# MSS_CTRL register map
Vendor: Texas Instruments
Peripheral module from a debugger description file (folder awr2x44p).
Registers are 32-bit, read-write, no defined reset value unless marked. A register's access mark holds for its fields unless they carry their own. Offsets are as the file gives them; lines under a group give offsets from that group; [hi:lo] are bit positions; {n}, {i} and the like mark numbered series; 'fields as' and 'values as' point back to an identical list; <NAME> marks a mode.

## MSS_CTRL (part 1 of 3)
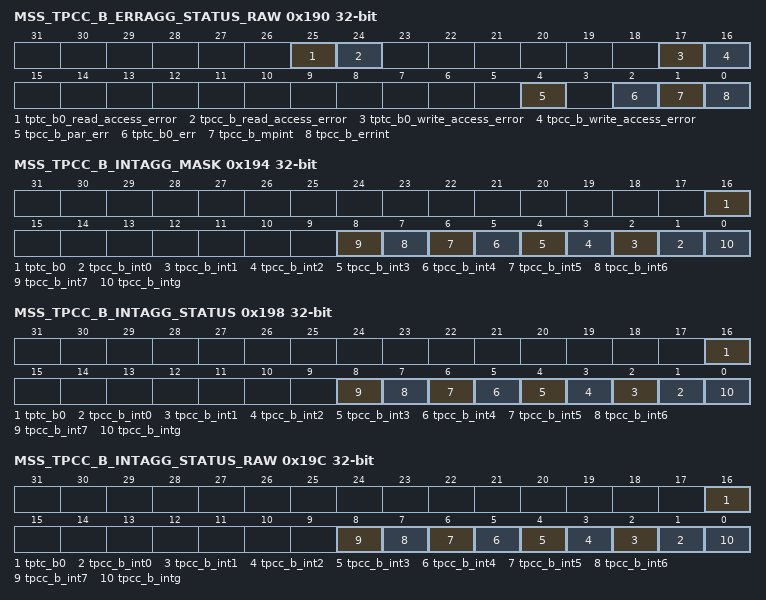
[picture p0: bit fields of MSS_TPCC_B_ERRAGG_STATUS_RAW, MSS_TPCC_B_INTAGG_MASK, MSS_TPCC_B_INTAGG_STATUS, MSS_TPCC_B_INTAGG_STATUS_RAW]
0x190 MSS_TPCC_B_ERRAGG_STATUS_RAW
  [25] tptc_b0_read_access_error — Rising Edge Capture reg (write 1 to clear): Raw Status of Error from MSS_TPTC_B0. Set irrespective if the Interupt is masked or unmasked in MSS_TPCC_B_ERRAGG_MASK
  [24] tpcc_b_read_access_error — Rising Edge Capture reg (write 1 to clear): Raw Status of Error from MSS_TPCC_B. Set irrespective if the Interupt is masked or unmasked in MSS_TPCC_B_ERRAGG_MASK
  [17] tptc_b0_write_access_error — Rising Edge Capture reg (write 1 to clear): Raw Status of Error from MSS_TPTC_B0. Set irrespective if the Interupt is masked or unmasked in MSS_TPCC_B_ERRAGG_MASK
  [16] tpcc_b_write_access_error — Rising Edge Capture reg (write 1 to clear): Raw Status of Error from MSS_TPCC_B. Set irrespective if the Interupt is masked or unmasked in MSS_TPCC_B_ERRAGG_MASK
  [4] tpcc_b_par_err — Rising Edge Capture reg (write 1 to clear): Raw Status of Error from MSS_TPCC_B. Set irrespective if the Interupt is masked or unmasked in MSS_TPCC_B_ERRAGG_MASK
  [2] tptc_b0_err — Rising Edge Capture reg (write 1 to clear): Raw Status of Error from MSS_TPTC_B0. Set irrespective if the Interupt is masked or unmasked in MSS_TPCC_B_ERRAGG_MASK
  [1] tpcc_b_mpint — Rising Edge Capture reg (write 1 to clear): Raw Status of Error from MSS_TPCC_B. Set irrespective if the Interupt is masked or unmasked in MSS_TPCC_B_ERRAGG_MASK
  [0] tpcc_b_errint — Rising Edge Capture reg (write 1 to clear): Raw Status of Error from MSS_TPCC_B. Set irrespective if the Interupt is masked or unmasked in MSS_TPCC_B_ERRAGG_MASK
0x194 MSS_TPCC_B_INTAGG_MASK
  [16] tptc_b0 — Mask Interrupt from TPTC A0 to aggregated Interrupt MSS_TPCC_A_INTAGG 1 : Interrupt is Masked 0 : Interrupt is Unmasked
  [n+1] tpcc_b_int{n} (n=0..7) — Mask Interrupt from MSS_TPCC_B to aggregated Interrupt MSS_TPCC_B_INTAGG 1 : Interrupt is Masked 0 : Interrupt is Unmasked
  [0] tpcc_b_intg — Mask Interrupt from MSS_TPCC_B to aggregated Interrupt MSS_TPCC_B_INTAGG 1 : Interrupt is Masked 0 : Interrupt is Unmasked
0x198 MSS_TPCC_B_INTAGG_STATUS
  [16] tptc_b0 — Rising Edge Capture reg (write 1 to clear): Status of Interrupt from TPTC A0. Set only if Interupt is unmasked in MSS_TPCC_A_INTAGG_MASK Wrie 0x1 to clear this interrupt.
  [n+1] tpcc_b_int{n} (n=0..7) — Rising Edge Capture reg (write 1 to clear): Status of Interrupt from MSS_TPCC_B. Set only if Interupt is unmasked in MSS_TPCC_B_INTAGG_MASK Wrie 0x1 to clear this interrupt.
  [0] tpcc_b_intg — Rising Edge Capture reg (write 1 to clear): Status of Interrupt from MSS_TPCC_B. Set only if Interupt is unmasked in MSS_TPCC_B_INTAGG_MASK Wrie 0x1 to clear this interrupt.
0x19C MSS_TPCC_B_INTAGG_STATUS_RAW
  [16] tptc_b0 — Rising Edge Capture reg (write 1 to clear): Raw Status of Interrupt from TPTC A0. Set irrespective if the Interupt is masked or unmasked in MSS_TPCC_A_INTAGG_MASK
  [n+1] tpcc_b_int{n} (n=0..7) — Rising Edge Capture reg (write 1 to clear): Raw Status of Interrupt from MSS_TPCC_B. Set irrespective if the Interupt is masked or unmasked in MSS_TPCC_C_INTAGG_MASK
  [0] tpcc_b_intg — Rising Edge Capture reg (write 1 to clear): Raw Status of Interrupt from MSS_TPCC_B. Set irrespective if the Interupt is masked or unmasked in MSS_TPCC_C_INTAGG_MASK
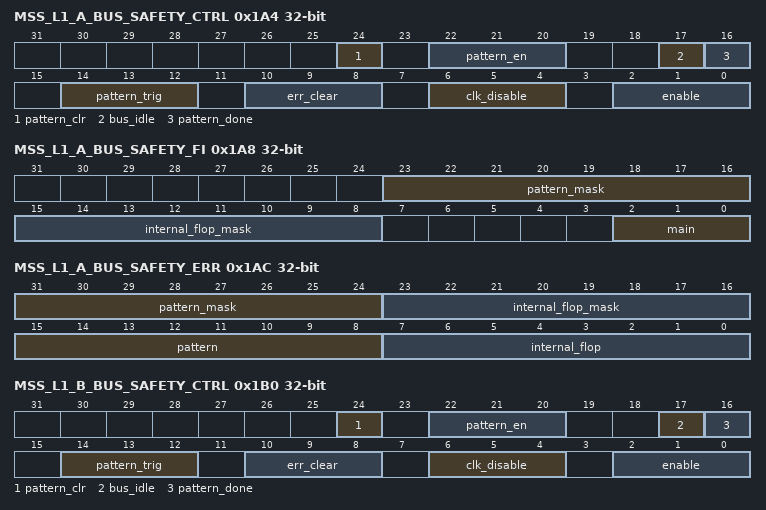
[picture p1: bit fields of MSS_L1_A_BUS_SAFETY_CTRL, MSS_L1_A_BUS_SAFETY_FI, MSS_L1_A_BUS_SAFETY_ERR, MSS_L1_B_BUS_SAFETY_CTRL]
0x1A4 MSS_L1_A_BUS_SAFETY_CTRL access per field
  [24] pattern_clr rw — Refer bus safety confluence page https://confluence.itg.ti.com/pages/viewpage.action?spaceKey=RadarPlatforms&title=Bus+Safety+-+AWR2944P
  [22:20] pattern_en rw — Refer bus safety confluence page https://confluence.itg.ti.com/pages/viewpage.action?spaceKey=RadarPlatforms&title=Bus+Safety+-+AWR2944P
  [17] bus_idle ro — Refer bus safety confluence page https://confluence.itg.ti.com/pages/viewpage.action?spaceKey=RadarPlatforms&title=Bus+Safety+-+AWR2944P
  [16] pattern_done ro — Refer bus safety confluence page https://confluence.itg.ti.com/pages/viewpage.action?spaceKey=RadarPlatforms&title=Bus+Safety+-+AWR2944P
  [14:12] pattern_trig rw — write pulse bit field:Refer bus safety confluence page https://confluence.itg.ti.com/pages/viewpage.action?spaceKey=RadarPlatforms&title=Bus+Safety+-+AWR2944P
  [10:8] err_clear rw — Refer bus safety confluence page https://confluence.itg.ti.com/pages/viewpage.action?spaceKey=RadarPlatforms&title=Bus+Safety+-+AWR2944P
  [6:4] clk_disable rw — Refer bus safety confluence page https://confluence.itg.ti.com/pages/viewpage.action?spaceKey=RadarPlatforms&title=Bus+Safety+-+AWR2944P
  [2:0] enable rw — Refer bus safety confluence page https://confluence.itg.ti.com/pages/viewpage.action?spaceKey=RadarPlatforms&title=Bus+Safety+-+AWR2944P
0x1A8 MSS_L1_A_BUS_SAFETY_FI
  [23:16] pattern_mask — Refer bus safety confluence page https://confluence.itg.ti.com/pages/viewpage.action?spaceKey=RadarPlatforms&title=Bus+Safety+-+AWR2944P
  [15:8] internal_flop_mask — Refer bus safety confluence page https://confluence.itg.ti.com/pages/viewpage.action?spaceKey=RadarPlatforms&title=Bus+Safety+-+AWR2944P
  [2:0] main — Refer bus safety confluence page https://confluence.itg.ti.com/pages/viewpage.action?spaceKey=RadarPlatforms&title=Bus+Safety+-+AWR2944P
0x1AC MSS_L1_A_BUS_SAFETY_ERR access per field
  [31:24] pattern_mask rw — Refer bus safety confluence page https://confluence.itg.ti.com/pages/viewpage.action?spaceKey=RadarPlatforms&title=Bus+Safety+-+AWR2944P
  [23:16] internal_flop_mask rw — Refer bus safety confluence page https://confluence.itg.ti.com/pages/viewpage.action?spaceKey=RadarPlatforms&title=Bus+Safety+-+AWR2944P
  [15:8] pattern ro — Refer bus safety confluence page https://confluence.itg.ti.com/pages/viewpage.action?spaceKey=RadarPlatforms&title=Bus+Safety+-+AWR2944P
  [7:0] internal_flop ro — Refer bus safety confluence page https://confluence.itg.ti.com/pages/viewpage.action?spaceKey=RadarPlatforms&title=Bus+Safety+-+AWR2944P
0x1B0 MSS_L1_B_BUS_SAFETY_CTRL access per field
  fields as MSS_L1_A_BUS_SAFETY_CTRL
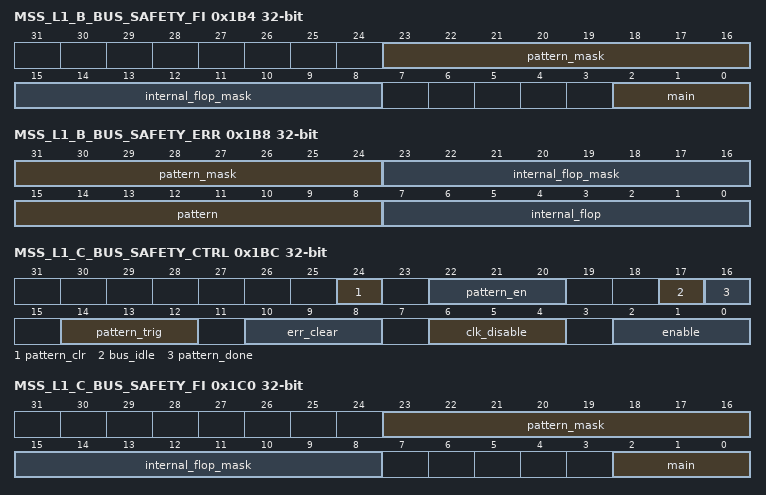
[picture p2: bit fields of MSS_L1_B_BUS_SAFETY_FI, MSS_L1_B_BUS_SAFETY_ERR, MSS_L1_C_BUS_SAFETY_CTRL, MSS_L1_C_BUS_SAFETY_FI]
0x1B4 MSS_L1_B_BUS_SAFETY_FI
  fields as MSS_L1_A_BUS_SAFETY_FI
0x1B8 MSS_L1_B_BUS_SAFETY_ERR access per field
  fields as MSS_L1_A_BUS_SAFETY_ERR
0x1BC MSS_L1_C_BUS_SAFETY_CTRL access per field
  fields as MSS_L1_A_BUS_SAFETY_CTRL
0x1C0 MSS_L1_C_BUS_SAFETY_FI
  fields as MSS_L1_A_BUS_SAFETY_FI
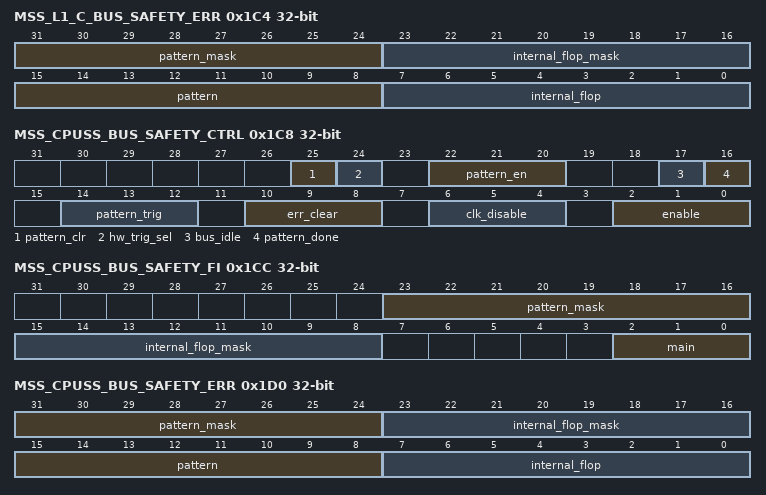
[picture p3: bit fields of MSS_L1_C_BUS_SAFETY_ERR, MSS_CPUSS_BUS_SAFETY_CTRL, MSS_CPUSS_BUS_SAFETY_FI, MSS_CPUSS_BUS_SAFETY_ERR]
0x1C4 MSS_L1_C_BUS_SAFETY_ERR access per field
  fields as MSS_L1_A_BUS_SAFETY_ERR
0x1C8 MSS_CPUSS_BUS_SAFETY_CTRL access per field
  [25] pattern_clr rw — Refer bus safety confluence page https://confluence.itg.ti.com/pages/viewpage.action?spaceKey=RadarPlatforms&title=Bus+Safety+-+AWR2944P
  [24] hw_trig_sel rw — Refer bus safety confluence page https://confluence.itg.ti.com/pages/viewpage.action?spaceKey=RadarPlatforms&title=Bus+Safety+-+AWR2944P
  [22:20] pattern_en rw — Refer bus safety confluence page https://confluence.itg.ti.com/pages/viewpage.action?spaceKey=RadarPlatforms&title=Bus+Safety+-+AWR2944P
  [17] bus_idle ro — Refer bus safety confluence page https://confluence.itg.ti.com/pages/viewpage.action?spaceKey=RadarPlatforms&title=Bus+Safety+-+AWR2944P
  [16] pattern_done ro — Refer bus safety confluence page https://confluence.itg.ti.com/pages/viewpage.action?spaceKey=RadarPlatforms&title=Bus+Safety+-+AWR2944P
  [14:12] pattern_trig rw — write pulse bit field:Refer bus safety confluence page https://confluence.itg.ti.com/pages/viewpage.action?spaceKey=RadarPlatforms&title=Bus+Safety+-+AWR2944P
  [10:8] err_clear rw — Refer bus safety confluence page https://confluence.itg.ti.com/pages/viewpage.action?spaceKey=RadarPlatforms&title=Bus+Safety+-+AWR2944P
  [6:4] clk_disable rw — Refer bus safety confluence page https://confluence.itg.ti.com/pages/viewpage.action?spaceKey=RadarPlatforms&title=Bus+Safety+-+AWR2944P
  [2:0] enable rw — Refer bus safety confluence page https://confluence.itg.ti.com/pages/viewpage.action?spaceKey=RadarPlatforms&title=Bus+Safety+-+AWR2944P
0x1CC MSS_CPUSS_BUS_SAFETY_FI
  fields as MSS_L1_A_BUS_SAFETY_FI
0x1D0 MSS_CPUSS_BUS_SAFETY_ERR access per field
  fields as MSS_L1_A_BUS_SAFETY_ERR
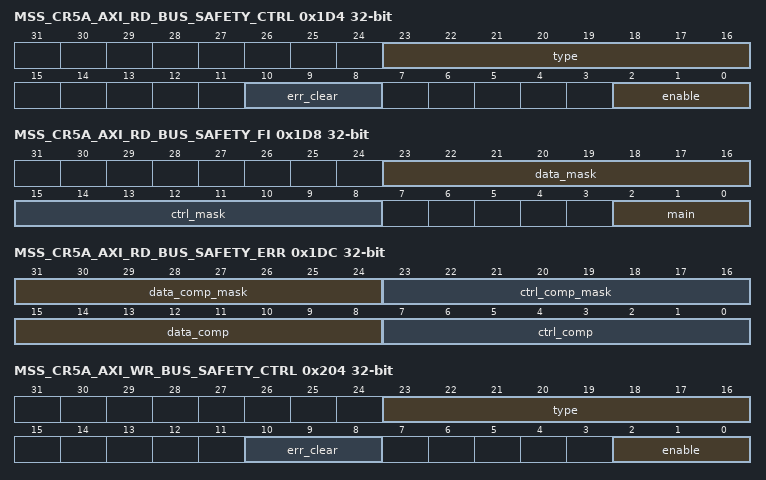
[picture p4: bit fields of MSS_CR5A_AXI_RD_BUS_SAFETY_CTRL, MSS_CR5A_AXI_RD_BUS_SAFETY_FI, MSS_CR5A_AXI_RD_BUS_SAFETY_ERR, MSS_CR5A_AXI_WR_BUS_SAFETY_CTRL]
0x1D4 MSS_CR5A_AXI_RD_BUS_SAFETY_CTRL access per field
  [23:16] type ro — undefined : command channel undefined : write channel undefined : write status channel undefined : read channel
  [10:8] err_clear rw — write pulse bit field:Refer bus safety confluence page https://confluence.itg.ti.com/pages/viewpage.action?spaceKey=RadarPlatforms&title=Bus+Safety+-+AWR2944P
  [2:0] enable rw — Refer bus safety confluence page https://confluence.itg.ti.com/pages/viewpage.action?spaceKey=RadarPlatforms&title=Bus+Safety+-+AWR2944P
0x1D8 MSS_CR5A_AXI_RD_BUS_SAFETY_FI
  [23:16] data_mask — Refer bus safety confluence page https://confluence.itg.ti.com/pages/viewpage.action?spaceKey=RadarPlatforms&title=Bus+Safety+-+AWR2944P
  [15:8] ctrl_mask — Refer bus safety confluence page https://confluence.itg.ti.com/pages/viewpage.action?spaceKey=RadarPlatforms&title=Bus+Safety+-+AWR2944P
  [2:0] main — Refer bus safety confluence page https://confluence.itg.ti.com/pages/viewpage.action?spaceKey=RadarPlatforms&title=Bus+Safety+-+AWR2944P
0x1DC MSS_CR5A_AXI_RD_BUS_SAFETY_ERR access per field
  [31:24] data_comp_mask rw — Refer bus safety confluence page https://confluence.itg.ti.com/pages/viewpage.action?spaceKey=RadarPlatforms&title=Bus+Safety+-+AWR2944P
  [23:16] ctrl_comp_mask rw — Refer bus safety confluence page https://confluence.itg.ti.com/pages/viewpage.action?spaceKey=RadarPlatforms&title=Bus+Safety+-+AWR2944P
  [15:8] data_comp ro — Refer bus safety confluence page https://confluence.itg.ti.com/pages/viewpage.action?spaceKey=RadarPlatforms&title=Bus+Safety+-+AWR2944P
  [7:0] ctrl_comp ro — Refer bus safety confluence page https://confluence.itg.ti.com/pages/viewpage.action?spaceKey=RadarPlatforms&title=Bus+Safety+-+AWR2944P
0x204 MSS_CR5A_AXI_WR_BUS_SAFETY_CTRL access per field
  fields as MSS_CR5A_AXI_RD_BUS_SAFETY_CTRL
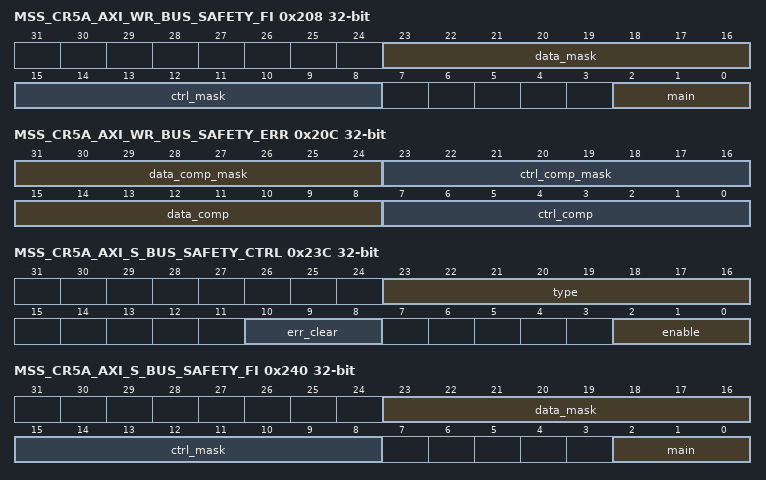
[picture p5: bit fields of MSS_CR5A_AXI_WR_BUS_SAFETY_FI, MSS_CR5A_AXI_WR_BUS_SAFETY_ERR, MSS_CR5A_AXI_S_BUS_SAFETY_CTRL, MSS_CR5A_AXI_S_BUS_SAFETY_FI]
0x208 MSS_CR5A_AXI_WR_BUS_SAFETY_FI
  fields as MSS_CR5A_AXI_RD_BUS_SAFETY_FI
0x20C MSS_CR5A_AXI_WR_BUS_SAFETY_ERR access per field
  fields as MSS_CR5A_AXI_RD_BUS_SAFETY_ERR
0x23C MSS_CR5A_AXI_S_BUS_SAFETY_CTRL access per field
  fields as MSS_CR5A_AXI_RD_BUS_SAFETY_CTRL
0x240 MSS_CR5A_AXI_S_BUS_SAFETY_FI
  fields as MSS_CR5A_AXI_RD_BUS_SAFETY_FI
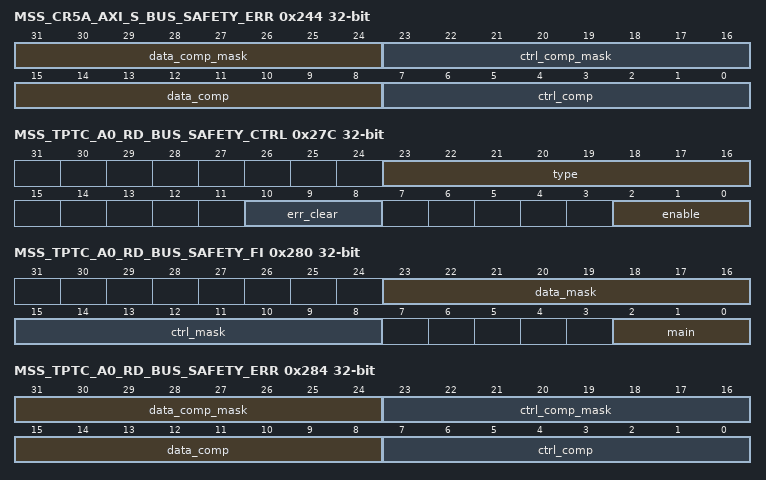
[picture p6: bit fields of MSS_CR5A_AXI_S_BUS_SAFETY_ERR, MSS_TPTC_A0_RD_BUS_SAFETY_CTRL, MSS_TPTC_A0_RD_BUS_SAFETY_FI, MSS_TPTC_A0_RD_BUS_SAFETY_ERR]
0x244 MSS_CR5A_AXI_S_BUS_SAFETY_ERR access per field
  fields as MSS_CR5A_AXI_RD_BUS_SAFETY_ERR
0x27C MSS_TPTC_A0_RD_BUS_SAFETY_CTRL access per field
  fields as MSS_CR5A_AXI_RD_BUS_SAFETY_CTRL
0x280 MSS_TPTC_A0_RD_BUS_SAFETY_FI
  fields as MSS_CR5A_AXI_RD_BUS_SAFETY_FI
0x284 MSS_TPTC_A0_RD_BUS_SAFETY_ERR access per field
  fields as MSS_CR5A_AXI_RD_BUS_SAFETY_ERR
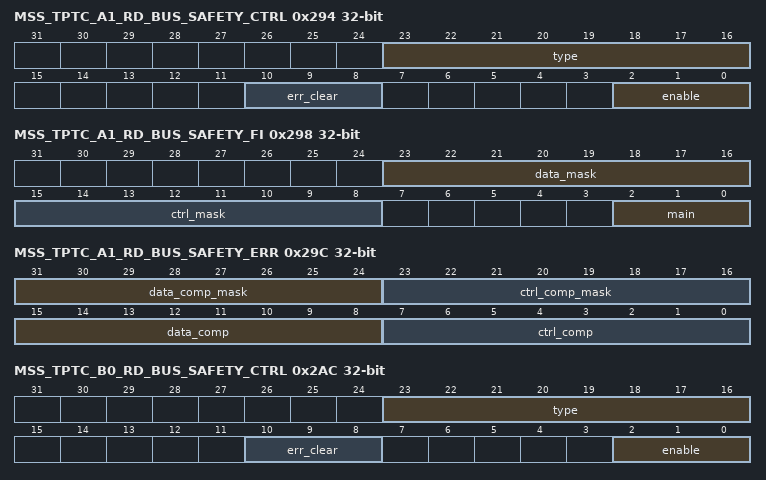
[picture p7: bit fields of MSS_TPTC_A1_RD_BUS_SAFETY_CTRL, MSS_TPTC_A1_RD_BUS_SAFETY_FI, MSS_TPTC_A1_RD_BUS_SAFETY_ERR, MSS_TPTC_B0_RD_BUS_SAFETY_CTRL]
0x294 MSS_TPTC_A1_RD_BUS_SAFETY_CTRL access per field
  fields as MSS_CR5A_AXI_RD_BUS_SAFETY_CTRL
0x298 MSS_TPTC_A1_RD_BUS_SAFETY_FI
  fields as MSS_CR5A_AXI_RD_BUS_SAFETY_FI
0x29C MSS_TPTC_A1_RD_BUS_SAFETY_ERR access per field
  fields as MSS_CR5A_AXI_RD_BUS_SAFETY_ERR
0x2AC MSS_TPTC_B0_RD_BUS_SAFETY_CTRL access per field
  fields as MSS_CR5A_AXI_RD_BUS_SAFETY_CTRL
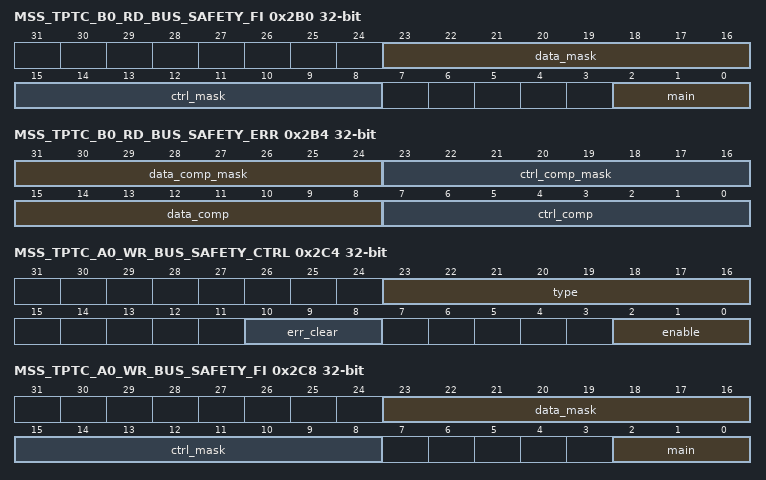
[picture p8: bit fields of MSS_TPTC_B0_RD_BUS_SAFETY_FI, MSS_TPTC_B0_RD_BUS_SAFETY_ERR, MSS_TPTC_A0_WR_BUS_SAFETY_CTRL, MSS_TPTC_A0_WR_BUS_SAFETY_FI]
0x2B0 MSS_TPTC_B0_RD_BUS_SAFETY_FI
  fields as MSS_CR5A_AXI_RD_BUS_SAFETY_FI
0x2B4 MSS_TPTC_B0_RD_BUS_SAFETY_ERR access per field
  fields as MSS_CR5A_AXI_RD_BUS_SAFETY_ERR
0x2C4 MSS_TPTC_A0_WR_BUS_SAFETY_CTRL access per field
  fields as MSS_CR5A_AXI_RD_BUS_SAFETY_CTRL
0x2C8 MSS_TPTC_A0_WR_BUS_SAFETY_FI
  fields as MSS_CR5A_AXI_RD_BUS_SAFETY_FI
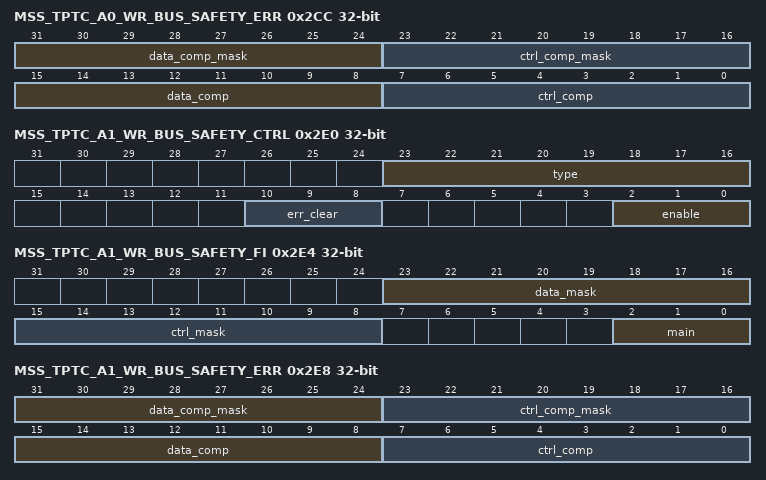
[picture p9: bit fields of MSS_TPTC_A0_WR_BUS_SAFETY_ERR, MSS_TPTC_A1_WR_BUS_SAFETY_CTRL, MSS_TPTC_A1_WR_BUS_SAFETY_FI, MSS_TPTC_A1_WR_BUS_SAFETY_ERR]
0x2CC MSS_TPTC_A0_WR_BUS_SAFETY_ERR access per field
  fields as MSS_CR5A_AXI_RD_BUS_SAFETY_ERR
0x2E0 MSS_TPTC_A1_WR_BUS_SAFETY_CTRL access per field
  fields as MSS_CR5A_AXI_RD_BUS_SAFETY_CTRL
0x2E4 MSS_TPTC_A1_WR_BUS_SAFETY_FI
  fields as MSS_CR5A_AXI_RD_BUS_SAFETY_FI
0x2E8 MSS_TPTC_A1_WR_BUS_SAFETY_ERR access per field
  fields as MSS_CR5A_AXI_RD_BUS_SAFETY_ERR
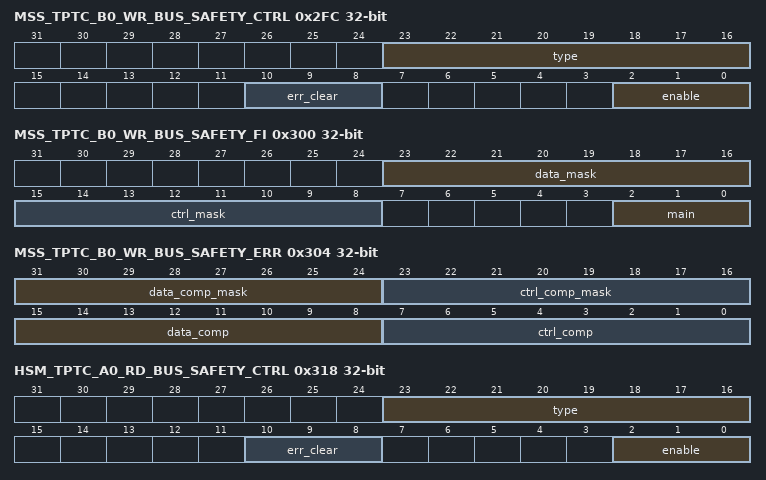
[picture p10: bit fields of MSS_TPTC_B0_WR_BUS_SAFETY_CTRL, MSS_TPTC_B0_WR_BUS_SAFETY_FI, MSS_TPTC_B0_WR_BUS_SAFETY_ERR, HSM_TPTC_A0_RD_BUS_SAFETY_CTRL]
0x2FC MSS_TPTC_B0_WR_BUS_SAFETY_CTRL access per field
  fields as MSS_CR5A_AXI_RD_BUS_SAFETY_CTRL
0x300 MSS_TPTC_B0_WR_BUS_SAFETY_FI
  fields as MSS_CR5A_AXI_RD_BUS_SAFETY_FI
0x304 MSS_TPTC_B0_WR_BUS_SAFETY_ERR access per field
  fields as MSS_CR5A_AXI_RD_BUS_SAFETY_ERR
0x318 HSM_TPTC_A0_RD_BUS_SAFETY_CTRL access per field
  fields as MSS_CR5A_AXI_RD_BUS_SAFETY_CTRL
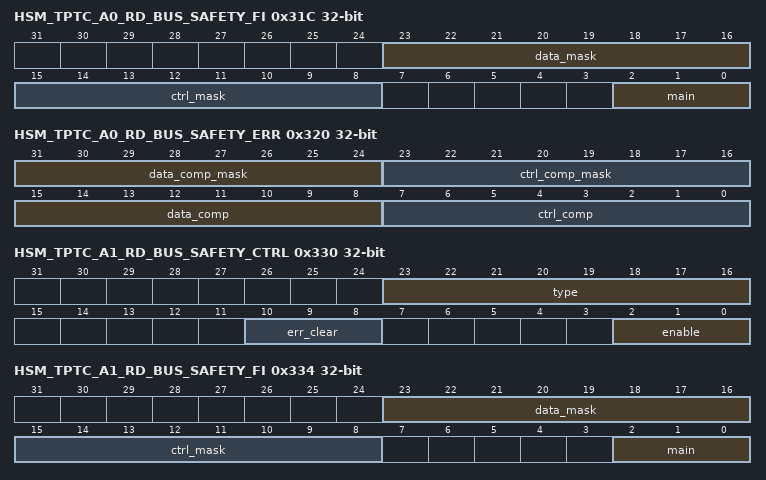
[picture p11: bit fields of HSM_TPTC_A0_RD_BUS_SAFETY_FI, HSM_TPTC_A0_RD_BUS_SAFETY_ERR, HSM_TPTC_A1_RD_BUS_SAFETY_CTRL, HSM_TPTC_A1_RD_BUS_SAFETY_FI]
0x31C HSM_TPTC_A0_RD_BUS_SAFETY_FI
  fields as MSS_CR5A_AXI_RD_BUS_SAFETY_FI
0x320 HSM_TPTC_A0_RD_BUS_SAFETY_ERR access per field
  fields as MSS_CR5A_AXI_RD_BUS_SAFETY_ERR
0x330 HSM_TPTC_A1_RD_BUS_SAFETY_CTRL access per field
  fields as MSS_CR5A_AXI_RD_BUS_SAFETY_CTRL
0x334 HSM_TPTC_A1_RD_BUS_SAFETY_FI
  fields as MSS_CR5A_AXI_RD_BUS_SAFETY_FI
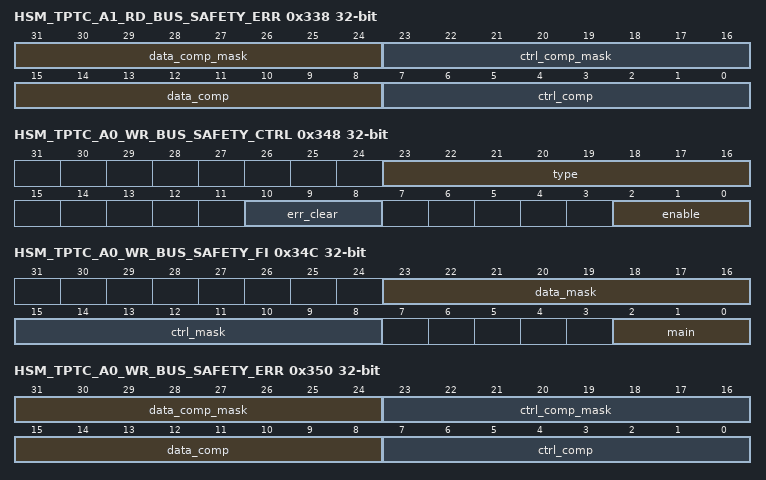
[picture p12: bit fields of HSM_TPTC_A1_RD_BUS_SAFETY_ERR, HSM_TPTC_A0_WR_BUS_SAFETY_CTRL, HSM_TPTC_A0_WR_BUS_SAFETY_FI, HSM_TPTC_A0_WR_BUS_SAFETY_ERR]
0x338 HSM_TPTC_A1_RD_BUS_SAFETY_ERR access per field
  fields as MSS_CR5A_AXI_RD_BUS_SAFETY_ERR
0x348 HSM_TPTC_A0_WR_BUS_SAFETY_CTRL access per field
  fields as MSS_CR5A_AXI_RD_BUS_SAFETY_CTRL
0x34C HSM_TPTC_A0_WR_BUS_SAFETY_FI
  fields as MSS_CR5A_AXI_RD_BUS_SAFETY_FI
0x350 HSM_TPTC_A0_WR_BUS_SAFETY_ERR access per field
  fields as MSS_CR5A_AXI_RD_BUS_SAFETY_ERR
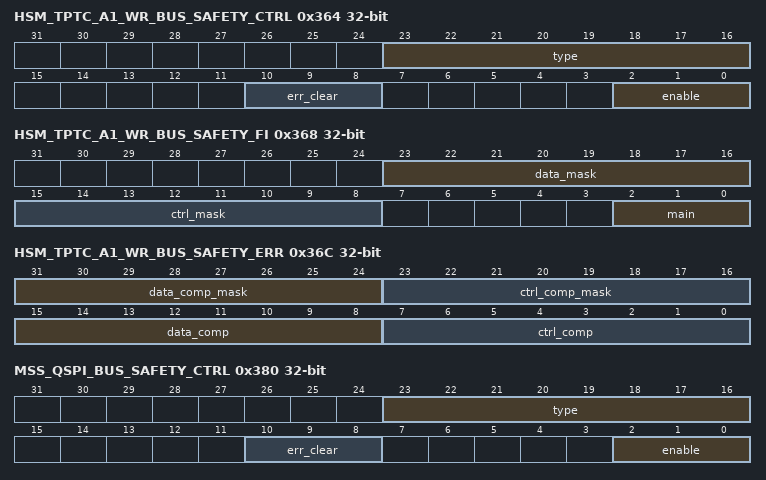
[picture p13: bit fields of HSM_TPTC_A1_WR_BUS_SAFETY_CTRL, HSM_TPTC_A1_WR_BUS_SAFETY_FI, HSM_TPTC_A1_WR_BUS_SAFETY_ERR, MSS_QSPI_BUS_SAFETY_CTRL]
0x364 HSM_TPTC_A1_WR_BUS_SAFETY_CTRL access per field
  fields as MSS_CR5A_AXI_RD_BUS_SAFETY_CTRL
0x368 HSM_TPTC_A1_WR_BUS_SAFETY_FI
  fields as MSS_CR5A_AXI_RD_BUS_SAFETY_FI
0x36C HSM_TPTC_A1_WR_BUS_SAFETY_ERR access per field
  fields as MSS_CR5A_AXI_RD_BUS_SAFETY_ERR
0x380 MSS_QSPI_BUS_SAFETY_CTRL access per field
  fields as MSS_CR5A_AXI_RD_BUS_SAFETY_CTRL
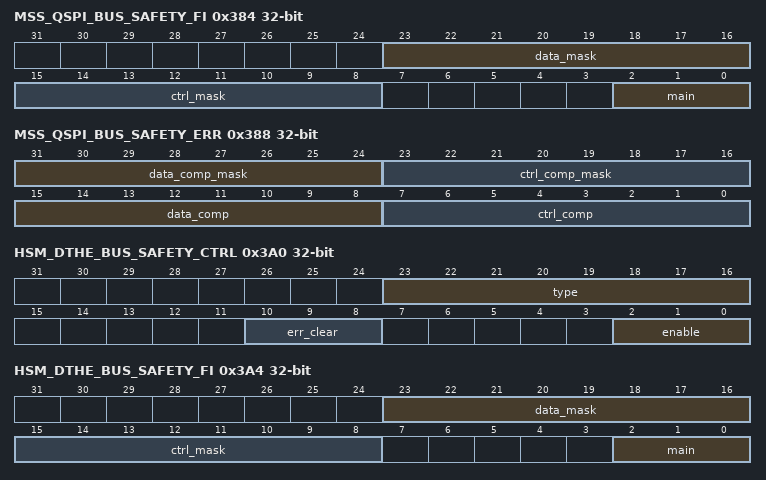
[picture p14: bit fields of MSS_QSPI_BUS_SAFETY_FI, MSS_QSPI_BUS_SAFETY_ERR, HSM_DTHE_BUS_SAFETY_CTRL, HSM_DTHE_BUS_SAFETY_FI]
0x384 MSS_QSPI_BUS_SAFETY_FI
  fields as MSS_CR5A_AXI_RD_BUS_SAFETY_FI
0x388 MSS_QSPI_BUS_SAFETY_ERR access per field
  fields as MSS_CR5A_AXI_RD_BUS_SAFETY_ERR
0x3A0 HSM_DTHE_BUS_SAFETY_CTRL access per field
  fields as MSS_CR5A_AXI_RD_BUS_SAFETY_CTRL
0x3A4 HSM_DTHE_BUS_SAFETY_FI
  fields as MSS_CR5A_AXI_RD_BUS_SAFETY_FI
0x3A8 HSM_DTHE_BUS_SAFETY_ERR access per field
  fields as MSS_CR5A_AXI_RD_BUS_SAFETY_ERR
0x3C0 MSS_CPSW_BUS_SAFETY_CTRL access per field
  fields as MSS_CR5A_AXI_RD_BUS_SAFETY_CTRL
0x3C4 MSS_CPSW_BUS_SAFETY_FI
  fields as MSS_CR5A_AXI_RD_BUS_SAFETY_FI
0x3C8 MSS_CPSW_BUS_SAFETY_ERR access per field
  fields as MSS_CR5A_AXI_RD_BUS_SAFETY_ERR
0x3E0 MSS_MCRC_BUS_SAFETY_CTRL access per field
  fields as MSS_CR5A_AXI_RD_BUS_SAFETY_CTRL
0x3E4 MSS_MCRC_BUS_SAFETY_FI
  fields as MSS_CR5A_AXI_RD_BUS_SAFETY_FI
0x3E8 MSS_MCRC_BUS_SAFETY_ERR access per field
  fields as MSS_CR5A_AXI_RD_BUS_SAFETY_ERR
0x400 MSS_PCR_BUS_SAFETY_CTRL access per field
  fields as MSS_CR5A_AXI_RD_BUS_SAFETY_CTRL
0x404 MSS_PCR_BUS_SAFETY_FI
  fields as MSS_CR5A_AXI_RD_BUS_SAFETY_FI
0x408 MSS_PCR_BUS_SAFETY_ERR access per field
  fields as MSS_CR5A_AXI_RD_BUS_SAFETY_ERR
0x420 MSS_PCR2_BUS_SAFETY_CTRL access per field
  fields as MSS_CR5A_AXI_RD_BUS_SAFETY_CTRL
0x424 MSS_PCR2_BUS_SAFETY_FI
  fields as MSS_CR5A_AXI_RD_BUS_SAFETY_FI
0x428 MSS_PCR2_BUS_SAFETY_ERR access per field
  fields as MSS_CR5A_AXI_RD_BUS_SAFETY_ERR
0x440 HSM_M_BUS_SAFETY_CTRL access per field
  fields as MSS_CR5A_AXI_RD_BUS_SAFETY_CTRL
0x444 HSM_M_BUS_SAFETY_FI
  fields as MSS_CR5A_AXI_RD_BUS_SAFETY_FI
0x448 HSM_M_BUS_SAFETY_ERR access per field
  fields as MSS_CR5A_AXI_RD_BUS_SAFETY_ERR
0x460 HSM_S_BUS_SAFETY_CTRL access per field
  fields as MSS_CR5A_AXI_RD_BUS_SAFETY_CTRL
0x464 HSM_S_BUS_SAFETY_FI
  fields as MSS_CR5A_AXI_RD_BUS_SAFETY_FI
0x468 HSM_S_BUS_SAFETY_ERR access per field
  fields as MSS_CR5A_AXI_RD_BUS_SAFETY_ERR
0x480 DAP_R232_BUS_SAFETY_CTRL access per field
  fields as MSS_CR5A_AXI_RD_BUS_SAFETY_CTRL
0x484 DAP_R232_BUS_SAFETY_FI
  fields as MSS_CR5A_AXI_RD_BUS_SAFETY_FI
0x488 DAP_R232_BUS_SAFETY_ERR access per field
  fields as MSS_CR5A_AXI_RD_BUS_SAFETY_ERR
0x4A0 MSS_L2_A_BUS_SAFETY_CTRL access per field
  fields as MSS_CR5A_AXI_RD_BUS_SAFETY_CTRL
0x4A4 MSS_L2_A_BUS_SAFETY_FI
  fields as MSS_CR5A_AXI_RD_BUS_SAFETY_FI
0x4A8 MSS_L2_A_BUS_SAFETY_ERR access per field
  fields as MSS_CR5A_AXI_RD_BUS_SAFETY_ERR
0x4C0 MSS_L2_B_BUS_SAFETY_CTRL access per field
  fields as MSS_CR5A_AXI_RD_BUS_SAFETY_CTRL
0x4C4 MSS_L2_B_BUS_SAFETY_FI
  fields as MSS_CR5A_AXI_RD_BUS_SAFETY_FI
0x4C8 MSS_L2_B_BUS_SAFETY_ERR access per field
  fields as MSS_CR5A_AXI_RD_BUS_SAFETY_ERR
0x4E0 MSS_MBOX_BUS_SAFETY_CTRL access per field
  fields as MSS_CR5A_AXI_RD_BUS_SAFETY_CTRL
0x4E4 MSS_MBOX_BUS_SAFETY_FI
  fields as MSS_CR5A_AXI_RD_BUS_SAFETY_FI
0x4E8 MSS_MBOX_BUS_SAFETY_ERR access per field
  fields as MSS_CR5A_AXI_RD_BUS_SAFETY_ERR
0x500 MSS_SWBUF_BUS_SAFETY_CTRL access per field
  fields as MSS_CR5A_AXI_RD_BUS_SAFETY_CTRL
0x504 MSS_SWBUF_BUS_SAFETY_FI
  fields as MSS_CR5A_AXI_RD_BUS_SAFETY_FI
0x508 MSS_SWBUF_BUS_SAFETY_ERR access per field
  fields as MSS_CR5A_AXI_RD_BUS_SAFETY_ERR
0x520 MSS_GPADC_BUS_SAFETY_CTRL access per field
  fields as MSS_CR5A_AXI_RD_BUS_SAFETY_CTRL
0x524 MSS_GPADC_BUS_SAFETY_FI
  fields as MSS_CR5A_AXI_RD_BUS_SAFETY_FI
0x528 MSS_GPADC_BUS_SAFETY_ERR access per field
  fields as MSS_CR5A_AXI_RD_BUS_SAFETY_ERR
0x548 HW_REG0
  [31:0] hwreg0 — HW reserved Regsiter
0x54C HW_REG1
  [31:0] hwreg1 — HW reserved Regsiter
0x550 PREVIOUS_NAME
  [31:1] hwreg2 — HW reserved Register
  [0] CPSW_CLK_STOP_REQ — CPSW clock stop req
0x554 HW_REG3 ro
  [31:9] hwreg3 — HW reserved Register
  [8] CPSW_CLK_STOP_IDLE — CPSW clock stop idle
  [4] CPSW_CLK_STOP_ACK — CPSW clock stop ack
  [0] ro — This denotes the status of ping_pong_sel bit.
0x558 HW_REG4
  [31:0] mss_pcrA_timeout_cfg — Configures the timeout value for MSS_PCRA.
{0x548+4i} HW_REG{i} (i=5..7)
  [31:0] hwreg{i} — HW reserved Register
0x568 MSS_DMM_BUS_SAFETY_CTRL access per field
  fields as MSS_CR5A_AXI_RD_BUS_SAFETY_CTRL
0x56C MSS_DMM_BUS_SAFETY_FI
  fields as MSS_CR5A_AXI_RD_BUS_SAFETY_FI
0x570 MSS_DMM_BUS_SAFETY_ERR access per field
  fields as MSS_CR5A_AXI_RD_BUS_SAFETY_ERR
0x588 MSS_DMM_SLV_BUS_SAFETY_CTRL access per field
  fields as MSS_CR5A_AXI_RD_BUS_SAFETY_CTRL
0x58C MSS_DMM_SLV_BUS_SAFETY_FI
  fields as MSS_CR5A_AXI_RD_BUS_SAFETY_FI
0x590 MSS_DMM_SLV_BUS_SAFETY_ERR access per field
  fields as MSS_CR5A_AXI_RD_BUS_SAFETY_ERR
0x5A8 MSS_TO_MDO_BUS_SAFETY_CTRL access per field
  fields as MSS_CR5A_AXI_RD_BUS_SAFETY_CTRL
0x5AC MSS_TO_MDO_BUS_SAFETY_FI
  fields as MSS_CR5A_AXI_RD_BUS_SAFETY_FI
0x5B0 MSS_TO_MDO_BUS_SAFETY_ERR access per field
  fields as MSS_CR5A_AXI_RD_BUS_SAFETY_ERR
0x5C8 MSS_SCRP_BUS_SAFETY_CTRL access per field
  [23:16] type ro — undefined : command channel undefined : write channel undefined : write status channel undefined : read channel
  [8] err_clear rw — write pulse bit field:Refer bus safety confluence page https://confluence.itg.ti.com/pages/viewpage.action?spaceKey=RadarPlatforms&title=Bus+Safety+-+AWR2944P
  [2:0] enable rw — Refer bus safety confluence page https://confluence.itg.ti.com/pages/viewpage.action?spaceKey=RadarPlatforms&title=Bus+Safety+-+AWR2944P
0x5CC MSS_SCRP_BUS_SAFETY_FI
  [31:24] safe — write pulse bit field:Refer bus safety confluence page https://confluence.itg.ti.com/pages/viewpage.action?spaceKey=RadarPlatforms&title=Bus+Safety+-+AWR2944P
  [23:16] main — write pulse bit field:Refer bus safety confluence page https://confluence.itg.ti.com/pages/viewpage.action?spaceKey=RadarPlatforms&title=Bus+Safety+-+AWR2944P
  [15:8] data — Refer bus safety confluence page https://confluence.itg.ti.com/pages/viewpage.action?spaceKey=RadarPlatforms&title=Bus+Safety+-+AWR2944P
  [5] ded — Refer bus safety confluence page https://confluence.itg.ti.com/pages/viewpage.action?spaceKey=RadarPlatforms&title=Bus+Safety+-+AWR2944P
  [4] sec — Refer bus safety confluence page https://confluence.itg.ti.com/pages/viewpage.action?spaceKey=RadarPlatforms&title=Bus+Safety+-+AWR2944P
  [3] global_safe_req — write pulse bit field:Refer bus safety confluence page https://confluence.itg.ti.com/pages/viewpage.action?spaceKey=RadarPlatforms&title=Bus+Safety+-+AWR2944P
  [2] global_main_req — write pulse bit field:Refer bus safety confluence page https://confluence.itg.ti.com/pages/viewpage.action?spaceKey=RadarPlatforms&title=Bus+Safety+-+AWR2944P
  [1] global_safe — write pulse bit field:Refer bus safety confluence page https://confluence.itg.ti.com/pages/viewpage.action?spaceKey=RadarPlatforms&title=Bus+Safety+-+AWR2944P
  [0] global_main — write pulse bit field:Refer bus safety confluence page https://confluence.itg.ti.com/pages/viewpage.action?spaceKey=RadarPlatforms&title=Bus+Safety+-+AWR2944P
0x5D0 MSS_SCRP_BUS_SAFETY_ERR ro
  [31:24] ded — Refer bus safety confluence page https://confluence.itg.ti.com/pages/viewpage.action?spaceKey=RadarPlatforms&title=Bus+Safety+-+AWR2944P
  [23:16] sec — Refer bus safety confluence page https://confluence.itg.ti.com/pages/viewpage.action?spaceKey=RadarPlatforms&title=Bus+Safety+-+AWR2944P
  [15:8] comp_check — Refer bus safety confluence page https://confluence.itg.ti.com/pages/viewpage.action?spaceKey=RadarPlatforms&title=Bus+Safety+-+AWR2944P
  [7:0] comp_err — Refer bus safety confluence page https://confluence.itg.ti.com/pages/viewpage.action?spaceKey=RadarPlatforms&title=Bus+Safety+-+AWR2944P
0x5D4 MSS_SCRP_BUS_SAFETY_ERR_STAT_DATA0 ro
  [15:8] d1 — Refer bus safety confluence page https://confluence.itg.ti.com/pages/viewpage.action?spaceKey=RadarPlatforms&title=Bus+Safety+-+AWR2944P
  [7:0] d0 — Refer bus safety confluence page https://confluence.itg.ti.com/pages/viewpage.action?spaceKey=RadarPlatforms&title=Bus+Safety+-+AWR2944P
0x5D8 MSS_SCRP_BUS_SAFETY_ERR_STAT_CMD ro
  [31:0] stat — Refer bus safety confluence page https://confluence.itg.ti.com/pages/viewpage.action?spaceKey=RadarPlatforms&title=Bus+Safety+-+AWR2944P
0x5DC MSS_SCRP_BUS_SAFETY_ERR_STAT_WRITE ro
  fields as MSS_SCRP_BUS_SAFETY_ERR_STAT_CMD
0x5E0 MSS_SCRP_BUS_SAFETY_ERR_STAT_READ ro
  fields as MSS_SCRP_BUS_SAFETY_ERR_STAT_CMD
0x5E4 MSS_SCRP_BUS_SAFETY_ERR_STAT_WRITERESP ro
  fields as MSS_SCRP_BUS_SAFETY_ERR_STAT_CMD
0x5E8 MSS_CR5A_AHB_BUS_SAFETY_CTRL access per field
  fields as MSS_SCRP_BUS_SAFETY_CTRL
0x5EC MSS_CR5A_AHB_BUS_SAFETY_FI
  fields as MSS_SCRP_BUS_SAFETY_FI
0x5F0 MSS_CR5A_AHB_BUS_SAFETY_ERR ro
  fields as MSS_SCRP_BUS_SAFETY_ERR
0x5F4 MSS_CR5A_AHB_BUS_SAFETY_ERR_STAT_DATA0 ro
  fields as MSS_SCRP_BUS_SAFETY_ERR_STAT_DATA0
0x5F8 MSS_CR5A_AHB_BUS_SAFETY_ERR_STAT_CMD ro
  fields as MSS_SCRP_BUS_SAFETY_ERR_STAT_CMD
0x5FC MSS_CR5A_AHB_BUS_SAFETY_ERR_STAT_WRITE ro
  fields as MSS_SCRP_BUS_SAFETY_ERR_STAT_CMD
0x600 MSS_CR5A_AHB_BUS_SAFETY_ERR_STAT_READ ro
  fields as MSS_SCRP_BUS_SAFETY_ERR_STAT_CMD
0x604 MSS_CR5A_AHB_BUS_SAFETY_ERR_STAT_WRITERESP ro
  fields as MSS_SCRP_BUS_SAFETY_ERR_STAT_CMD
0x628 DMM_CTRL_REG
  [0] dmm_pad_select — 0: SOC will be able to send the packet to DMMA/B 1: PAD will be able to send the packet to DMMA/B controlling from PAD
0x62C MSS_CR5A_MBOX_WRITE_DONE
  [4n] proc_{n} (n=0..7) — Write pulse bit field: This register should be written once finishing writing into the mailbox memory of processor {n}
0x630 MSS_CR5A_MBOX_READ_REQ
  [4n] proc_{n} (n=0..7) — Rising Edge Capture reg (write 1 to clear): This is request from processor {n} to mss_cr5a. Requesting it to read from mailbox.
0x634 MSS_CR5A_MBOX_READ_DONE
  [4n] proc_{n} (n=0..7) — Rising Edge Capture reg (write 1 to clear): This register should be written once finishing reading from CR5A's mailbox written by proc {n}
0x644 MSS_PBIST_KEY_RST
  [7:4] pbist_st_rst — MSS PBIST controller will be brought out of reset when value is 0xA
  [3:0] pbist_st_key — Top PBIST Selftest Key. Valid value is 0x5
{0x648+4i} MSS_PBIST_REG{i} (i=0..2)
  [31:0] pbist_reg — 0
0x654 MSS_QSPI_CONFIG
  [10:8] clk_loopback — Write 3'b111 to take board level loop back clock for QSPI
  [2:0] ext_clk — Write 3'b111 to external clock as QSPI baud clock source needed for DFT IO char.
0x658 MSS_STC_CONTROL
  [2:0] cr5_wfi_overide — writing 3'b111 will bypass the wfi signals from R5SS.
0x65C MSS_CTI_TRIG_SEL
  [7:0] trig8_sel — Used for selecting the trigger source for 8th trigger of MSS_CTI
0x660 MSS_DBGSS_CTI_TRIG_SEL
  [23:16] trig3 — Used for selecting the trigger source for 3rd trigger of ONE_MCU_CTI
  [15:8] trig2 — Used for selecting the trigger source for 2nd trigger of ONE_MCU_CTI
  [7:0] trig1 — Used for selecting the trigger source for 1st trigger of ONE_MCU_CTI
{0x664+4i} MSS_BOOT_INFO_REG{i} (i=0..7)
  [31:0] config — Reserved Register for Software use
0x684 MSS_TPTC_ECCAGGR_CLK_CNTRL
  [2] tptc_B0 — Writing '0' will gate the clock to TPTC_B0-FIFO during ECC-AGGR interaction(fault injection)
  [1] tptc_A1 — Writing '0' will gate the clock to TPTC_A1-FIFO during ECC-AGGR interaction(fault injection)
  [0] tptc_A0 — Writing '0' will gate the clock to TPTC_A0-FIFO during ECC-AGGR interaction(fault injection)
0x688 MSS_PERIPH_ERRAGG_MASK0
  [27] top_mdo_wr — Mask Interrupt from TOP_MDO to aggregated Interrupt MSS_PERIPH_ACCESS_ERRAGG 1 : Interrupt is Masked 0 : Interrupt is Unmasked
  [26] top_mdo_rd — Mask Interrupt from TOP_MDO to aggregated Interrupt MSS_PERIPH_ACCESS_ERRAGG 1 : Interrupt is Masked 0 : Interrupt is Unmasked
  [25] rcss_rcm_wr — Mask Interrupt from RSS_RCM to aggregated Interrupt MSS_PERIPH_ACCESS_ERRAGG 1 : Interrupt is Masked 0 : Interrupt is Unmasked
  [24] rcss_rcm_rd — Mask Interrupt from RSS_RCM to aggregated Interrupt MSS_PERIPH_ACCESS_ERRAGG 1 : Interrupt is Masked 0 : Interrupt is Unmasked
  [23] rcss_ctrl_wr — Mask Interrupt from RSS_CTRL to aggregated Interrupt MSS_PERIPH_ACCESS_ERRAGG 1 : Interrupt is Masked 0 : Interrupt is Unmasked
  [22] rcss_ctrl_rd — Mask Interrupt from RSS_CTRL to aggregated Interrupt MSS_PERIPH_ACCESS_ERRAGG 1 : Interrupt is Masked 0 : Interrupt is Unmasked
  [21] hwa_cfg_wr — Mask Interrupt from HWA_CFG to aggregated Interrupt MSS_PERIPH_ACCESS_ERRAGG 1 : Interrupt is Masked 0 : Interrupt is Unmasked
  [20] hwa_cfg_rd — Mask Interrupt from HWA_CFG to aggregated Interrupt MSS_PERIPH_ACCESS_ERRAGG 1 : Interrupt is Masked 0 : Interrupt is Unmasked
  [19] dss_cm4_ctrl_wr — Mask Interrupt from DSS_CM4_CTRL to aggregated Interrupt MSS_PERIPH_ACCESS_ERRAGG 1 : Interrupt is Masked 0 : Interrupt is Unmasked
  [18] dss_cm4_ctrl_rd — Mask Interrupt from DSS_CM4_CTRL to aggregated Interrupt MSS_PERIPH_ACCESS_ERRAGG 1 : Interrupt is Masked 0 : Interrupt is Unmasked
  [17] dss_rcm_wr — Mask Interrupt from DSS_RCM to aggregated Interrupt MSS_PERIPH_ACCESS_ERRAGG 1 : Interrupt is Masked 0 : Interrupt is Unmasked
  [16] dss_rcm_rd — Mask Interrupt from DSS_RCM to aggregated Interrupt MSS_PERIPH_ACCESS_ERRAGG 1 : Interrupt is Masked 0 : Interrupt is Unmasked
  [15] dss_ctrl_wr — Mask Interrupt from DSS_CTRL to aggregated Interrupt MSS_PERIPH_ACCESS_ERRAGG 1 : Interrupt is Masked 0 : Interrupt is Unmasked
  [14] dss_ctrl_rd — Mask Interrupt from DSS_CTRL to aggregated Interrupt MSS_PERIPH_ACCESS_ERRAGG 1 : Interrupt is Masked 0 : Interrupt is Unmasked
  [13] hsm_ctrl_wr — Mask Interrupt from HSM_CTRL to aggregated Interrupt MSS_PERIPH_ACCESS_ERRAGG 1 : Interrupt is Masked 0 : Interrupt is Unmasked
  [12] hsm_ctrl_rd — Mask Interrupt from HSM_CTRL to aggregated Interrupt MSS_PERIPH_ACCESS_ERRAGG 1 : Interrupt is Masked 0 : Interrupt is Unmasked
  [11] hsm_soc_ctrl_wr — Mask Interrupt from HSM_SOC_CTRL to aggregated Interrupt MSS_PERIPH_ACCESS_ERRAGG 1 : Interrupt is Masked 0 : Interrupt is Unmasked
  [10] hsm_soc_ctrl_rd — Mask Interrupt from HSM_SOC_CTRL to aggregated Interrupt MSS_PERIPH_ACCESS_ERRAGG 1 : Interrupt is Masked 0 : Interrupt is Unmasked
  [9] top_aurora_wr — Mask Interrupt from TOP_AURORA to aggregated Interrupt MSS_PERIPH_ACCESS_ERRAGG 1 : Interrupt is Masked 0 : Interrupt is Unmasked
  [8] top_aurora_rd — Mask Interrupt from TOP_AURORA to aggregated Interrupt MSS_PERIPH_ACCESS_ERRAGG 1 : Interrupt is Masked 0 : Interrupt is Unmasked
  [7] top_rcm_wr — Mask Interrupt from TOP_RCM to aggregated Interrupt MSS_PERIPH_ACCESS_ERRAGG 1 : Interrupt is Masked 0 : Interrupt is Unmasked
  [6] top_rcm_rd — Mask Interrupt from TOP_RCM to aggregated Interrupt MSS_PERIPH_ACCESS_ERRAGG 1 : Interrupt is Masked 0 : Interrupt is Unmasked
  [5] top_ctrl_wr — Mask Interrupt from TOP_CTRL to aggregated Interrupt MSS_PERIPH_ACCESS_ERRAGG 1 : Interrupt is Masked 0 : Interrupt is Unmasked
  [4] top_ctrl_rd — Mask Interrupt from TOP_CTRL to aggregated Interrupt MSS_PERIPH_ACCESS_ERRAGG 1 : Interrupt is Masked 0 : Interrupt is Unmasked
  [3] mss_rcm_wr — Mask Interrupt from MSS_RCM to aggregated Interrupt MSS_PERIPH_ACCESS_ERRAGG 1 : Interrupt is Masked 0 : Interrupt is Unmasked
  [2] mss_rcm_rd — Mask Interrupt from MSS_RCM to aggregated Interrupt MSS_PERIPH_ACCESS_ERRAGG 1 : Interrupt is Masked 0 : Interrupt is Unmasked
  [1] mss_ctrl_wr — Mask Interrupt from MSS_CTRL to aggregated Interrupt MSS_PERIPH_ACCESS_ERRAGG 1 : Interrupt is Masked 0 : Interrupt is Unmasked
  [0] mss_ctrl_rd — Mask Interrupt from MSS_CTRL to aggregated Interrupt MSS_PERIPH_ACCESS_ERRAGG 1 : Interrupt is Masked 0 : Interrupt is Unmasked
0x68C MSS_PERIPH_ERRAGG_STATUS0
  [27] top_mdo_wr — Rising Edge Capture reg (write 1 to clear): Status of Interrupt from TOP_MDO Set only if Interupt is unmasked in MSS_PERIPH_ERRAGG_MASK0 Wrie 0x1 to clear this interrupt.
  [26] top_mdo_rd — Rising Edge Capture reg (write 1 to clear): Status of Interrupt from TOP_MDO Set only if Interupt is unmasked in MSS_PERIPH_ERRAGG_MASK0 Wrie 0x1 to clear this interrupt.
  [25] rcss_rcm_wr — Rising Edge Capture reg (write 1 to clear): Status of Interrupt from RSS_RCM Set only if Interupt is unmasked in MSS_PERIPH_ERRAGG_MASK0 Wrie 0x1 to clear this interrupt.
  [24] rcss_rcm_rd — Rising Edge Capture reg (write 1 to clear): Status of Interrupt from RSS_RCM Set only if Interupt is unmasked in MSS_PERIPH_ERRAGG_MASK0 Wrie 0x1 to clear this interrupt.
  [23] rcss_ctrl_wr — Rising Edge Capture reg (write 1 to clear): Status of Interrupt from RSS_CTRL Set only if Interupt is unmasked in MSS_PERIPH_ERRAGG_MASK0 Wrie 0x1 to clear this interrupt.
  [22] rcss_ctrl_rd — Rising Edge Capture reg (write 1 to clear): Status of Interrupt from RSS_CTRL Set only if Interupt is unmasked in MSS_PERIPH_ERRAGG_MASK0 Wrie 0x1 to clear this interrupt.
  [21] hwa_cfg_wr — Rising Edge Capture reg (write 1 to clear): Status of Interrupt from HWA_CFG Set only if Interupt is unmasked in MSS_PERIPH_ERRAGG_MASK0 Wrie 0x1 to clear this interrupt.
  [20] hwa_cfg_rd — Rising Edge Capture reg (write 1 to clear): Status of Interrupt from HWA_CFG Set only if Interupt is unmasked in MSS_PERIPH_ERRAGG_MASK0 Wrie 0x1 to clear this interrupt.
  [19] dss_cm4_ctrl_wr — Rising Edge Capture reg (write 1 to clear): Status of Interrupt from DSS_CM4_CTRL Set only if Interupt is unmasked in MSS_PERIPH_ERRAGG_MASK0 Wrie 0x1 to clear this interrupt.
  [18] dss_cm4_ctrl_rd — Rising Edge Capture reg (write 1 to clear): Status of Interrupt from DSS_CM4_CTRL Set only if Interupt is unmasked in MSS_PERIPH_ERRAGG_MASK0 Wrie 0x1 to clear this interrupt.
  [17] dss_rcm_wr — Rising Edge Capture reg (write 1 to clear): Status of Interrupt from DSS_RCM Set only if Interupt is unmasked in MSS_PERIPH_ERRAGG_MASK0 Wrie 0x1 to clear this interrupt.
  [16] dss_rcm_rd — Rising Edge Capture reg (write 1 to clear): Status of Interrupt from DSS_RCM Set only if Interupt is unmasked in MSS_PERIPH_ERRAGG_MASK0 Wrie 0x1 to clear this interrupt.
  [15] dss_ctrl_wr — Rising Edge Capture reg (write 1 to clear): Status of Interrupt from DSS_CTRL Set only if Interupt is unmasked in MSS_PERIPH_ERRAGG_MASK0 Wrie 0x1 to clear this interrupt.
  [14] dss_ctrl_rd — Rising Edge Capture reg (write 1 to clear): Status of Interrupt from DSS_CTRL Set only if Interupt is unmasked in MSS_PERIPH_ERRAGG_MASK0 Wrie 0x1 to clear this interrupt.
  [13] hsm_ctrl_wr — Rising Edge Capture reg (write 1 to clear): Status of Interrupt from HSM_CTRL Set only if Interupt is unmasked in MSS_PERIPH_ERRAGG_MASK0 Wrie 0x1 to clear this interrupt.
  [12] hsm_ctrl_rd — Rising Edge Capture reg (write 1 to clear): Status of Interrupt from HSM_CTRL Set only if Interupt is unmasked in MSS_PERIPH_ERRAGG_MASK0 Wrie 0x1 to clear this interrupt.
  [11] hsm_soc_ctrl_wr — Rising Edge Capture reg (write 1 to clear): Status of Interrupt from HSM_SOC_CTRL Set only if Interupt is unmasked in MSS_PERIPH_ERRAGG_MASK0 Wrie 0x1 to clear this interrupt.
  [10] hsm_soc_ctrl_rd — Rising Edge Capture reg (write 1 to clear): Status of Interrupt from HSM_SOC_CTRL Set only if Interupt is unmasked in MSS_PERIPH_ERRAGG_MASK0 Wrie 0x1 to clear this interrupt.
  [9] top_aurora_wr — Rising Edge Capture reg (write 1 to clear): Status of Interrupt from TOP_AURORA Set only if Interupt is unmasked in MSS_PERIPH_ERRAGG_MASK0 Wrie 0x1 to clear this interrupt.
  [8] top_aurora_rd — Rising Edge Capture reg (write 1 to clear): Status of Interrupt from TOP_AURORA Set only if Interupt is unmasked in MSS_PERIPH_ERRAGG_MASK0 Wrie 0x1 to clear this interrupt.
  [7] top_rcm_wr — Rising Edge Capture reg (write 1 to clear): Status of Interrupt from TOP_RCM Set only if Interupt is unmasked in MSS_PERIPH_ERRAGG_MASK0 Wrie 0x1 to clear this interrupt.
  [6] top_rcm_rd — Rising Edge Capture reg (write 1 to clear): Status of Interrupt from TOP_RCM Set only if Interupt is unmasked in MSS_PERIPH_ERRAGG_MASK0 Wrie 0x1 to clear this interrupt.
  [5] top_ctrl_wr — Rising Edge Capture reg (write 1 to clear): Status of Interrupt from TOP_CTRL Set only if Interupt is unmasked in MSS_PERIPH_ERRAGG_MASK0 Wrie 0x1 to clear this interrupt.
  [4] top_ctrl_rd — Rising Edge Capture reg (write 1 to clear): Status of Interrupt from TOP_CTRL Set only if Interupt is unmasked in MSS_PERIPH_ERRAGG_MASK0 Wrie 0x1 to clear this interrupt.
  [3] mss_rcm_wr — Rising Edge Capture reg (write 1 to clear): Status of Interrupt from MSS_RCM Set only if Interupt is unmasked in MSS_PERIPH_ERRAGG_MASK0 Wrie 0x1 to clear this interrupt.
  [2] mss_rcm_rd — Rising Edge Capture reg (write 1 to clear): Status of Interrupt from MSS_RCM Set only if Interupt is unmasked in MSS_PERIPH_ERRAGG_MASK0 Wrie 0x1 to clear this interrupt.
  [1] mss_ctrl_wr — Rising Edge Capture reg (write 1 to clear): Status of Interrupt from MSS_CTRL Set only if Interupt is unmasked in MSS_PERIPH_ERRAGG_MASK0 Wrie 0x1 to clear this interrupt.
  [0] mss_ctrl_rd — Rising Edge Capture reg (write 1 to clear): Status of Interrupt from MSS_CTRL Set only if Interupt is unmasked in MSS_PERIPH_ERRAGG_MASK0 Wrie 0x1 to clear this interrupt.
